AUTOSAR XML (schema 4-2-2)
package /ComponentTypes
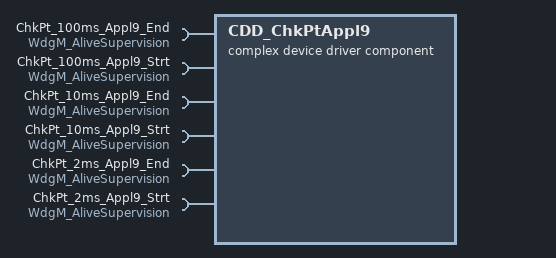
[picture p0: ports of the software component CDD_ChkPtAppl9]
  complex device driver sw component type CDD_ChkPtAppl9
    6 x require port, all with client-com-spec=CheckpointReached, required-interface=WdgM_AliveSupervision:
      ChkPt_100ms_Appl9_End
      ChkPt_100ms_Appl9_Strt
      ChkPt_10ms_Appl9_End
      ChkPt_10ms_Appl9_Strt
      ChkPt_2ms_Appl9_End
      ChkPt_2ms_Appl9_Strt
    behavior CDD_ChkPtAppl9_InternalBehavior
      6 x timing event:
        TMT_ChkPt_100msAppl9End: start-on-event=ChkPt_100msAppl9End, period=0.1
        TMT_ChkPt_100msAppl9Strt: start-on-event=ChkPt_100msAppl9Strt, period=0.1
        TMT_ChkPt_10msAppl9End: start-on-event=ChkPt_10msAppl9End, period=0.01
        TMT_ChkPt_10msAppl9Strt: start-on-event=ChkPt_10msAppl9Strt, period=0.01
        TMT_ChkPt_2msAppl9End: start-on-event=ChkPt_2msAppl9End, period=0.002
        TMT_ChkPt_2msAppl9Strt: start-on-event=ChkPt_2msAppl9Strt, period=0.002
      port-api-options:
        enable-take-address=false, error-handling=NO-TRANSFORMER-ERROR-HANDLING, indirect-api=false, port=ChkPt_100ms_Appl9_End
        enable-take-address=false, error-handling=NO-TRANSFORMER-ERROR-HANDLING, indirect-api=false, port=ChkPt_100ms_Appl9_Strt
        enable-take-address=false, error-handling=NO-TRANSFORMER-ERROR-HANDLING, indirect-api=false, port=ChkPt_10ms_Appl9_End
        enable-take-address=false, error-handling=NO-TRANSFORMER-ERROR-HANDLING, indirect-api=false, port=ChkPt_10ms_Appl9_Strt
        enable-take-address=false, error-handling=NO-TRANSFORMER-ERROR-HANDLING, indirect-api=false, port=ChkPt_2ms_Appl9_End
        enable-take-address=false, error-handling=NO-TRANSFORMER-ERROR-HANDLING, indirect-api=false, port=ChkPt_2ms_Appl9_Strt
      6 x runnable:
        ChkPt_100msAppl9End
          sync call SC_ChkPt_100ms_Appl9_End_CheckpointReached: operation=ChkPt_100ms_Appl9_End.CheckpointReached, timeout=0
        ChkPt_100msAppl9Strt
          sync call SC_ChkPt_100ms_Appl9_Strt_CheckpointReached: operation=ChkPt_100ms_Appl9_Strt.CheckpointReached, timeout=0
        ChkPt_10msAppl9End
          sync call SC_ChkPt_10ms_Appl9_End_CheckpointReached: operation=ChkPt_10ms_Appl9_End.CheckpointReached, timeout=0
        ChkPt_10msAppl9Strt
          sync call SC_ChkPt_10ms_Appl9_Strt_CheckpointReached: operation=ChkPt_10ms_Appl9_Strt.CheckpointReached, timeout=0
        ChkPt_2msAppl9End
          sync call SC_ChkPt_2ms_Appl9_End_CheckpointReached: operation=ChkPt_2ms_Appl9_End.CheckpointReached, timeout=0
        ChkPt_2msAppl9Strt
          sync call SC_ChkPt_2ms_Appl9_Strt_CheckpointReached: operation=ChkPt_2ms_Appl9_Strt.CheckpointReached, timeout=0
  swc implementation CDD_ChkPtAppl9_Implementation: behavior=CDD_ChkPtAppl9_InternalBehavior
    code-descriptors:
      code Default: artifact-descriptors=autosar-engineering-object={short-label=Default, category=SWSRC}
